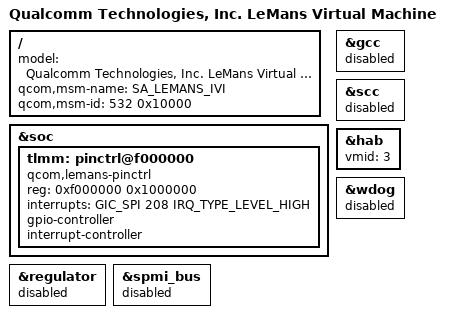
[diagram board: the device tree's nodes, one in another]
#include "quin-vm-common.dtsi"

/ {
	model = "Qualcomm Technologies, Inc. LeMans Virtual Machine";
	qcom,msm-name = "SA_LEMANS_IVI";
	qcom,msm-id = <532 0x10000>;
};

&soc {
	tlmm: pinctrl@f000000 {
		compatible = "qcom,lemans-pinctrl";
		reg = <0xf000000 0x1000000>;
		interrupts = <GIC_SPI 208 IRQ_TYPE_LEVEL_HIGH>;
		gpio-controller;
		#gpio-cells = <2>;
		interrupt-controller;
		#interrupt-cells = <2>;
	};
};

&gcc {
	status = "disabled";
};

&scc {
	status = "disabled";
};

&regulator {
	status = "disabled";
};

&hab {
	vmid = <3>;
};

&spmi_bus {
	status = "disabled";
};

&wdog {
	status = "disabled";
};
